AUTOSAR XML (schema 4-2-1)
package /ComponentTypes
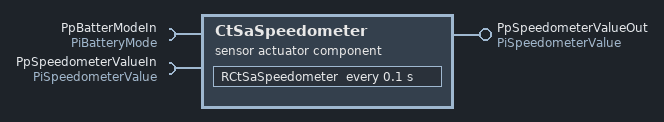
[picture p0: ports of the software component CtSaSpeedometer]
  sensor actuator sw component type CtSaSpeedometer
    provide port PpSpeedometerValueOut: nonqueued-sender-com-spec{data-element=DeSpeedometerValue, init-value=constant-reference=CInitSpeed}, provided-interface=PiSpeedometerValue
    require port PpBatterModeIn: mode-switch-receiver-com-spec{enhanced-mode-api=false, supports-asynchronous-mode-switch=false}, required-interface=PiBatteryMode
    require port PpSpeedometerValueIn: nonqueued-receiver-com-spec{data-element=DeSpeedometerValue, filter=data-filter-type=ALWAYS, init-value=constant-reference=CInitSpeed}, required-interface=PiSpeedometerValue
    behavior CtSaSpeedometer_InternalBehavior: data-type-mapping=ApMappingSet
      timing event TMT_RCtSaSpeedometer: disabled-mode=PpBatterModeIn.BatteryModes.BATTERY_LOW, start-on-event=RCtSaSpeedometer, period=0.1
      runnable RCtSaSpeedometer
        data-receive-point-by-arguments:
          access REC_PpSpeedometerValueIn_DeSpeedometerValue: accessed-variable=PpSpeedometerValueIn.DeSpeedometerValue
        data-send-points:
          access SEND_PpSpeedometerValueOut_DeSpeedometerValue: accessed-variable=PpSpeedometerValueOut.DeSpeedometerValue
  swc implementation CtSaSpeedometer_Implementation: behavior=CtSaSpeedometer_InternalBehavior
    code-descriptors:
      code Default: artifact-descriptors=autosar-engineering-object={short-label=Default, category=SWSRC}
